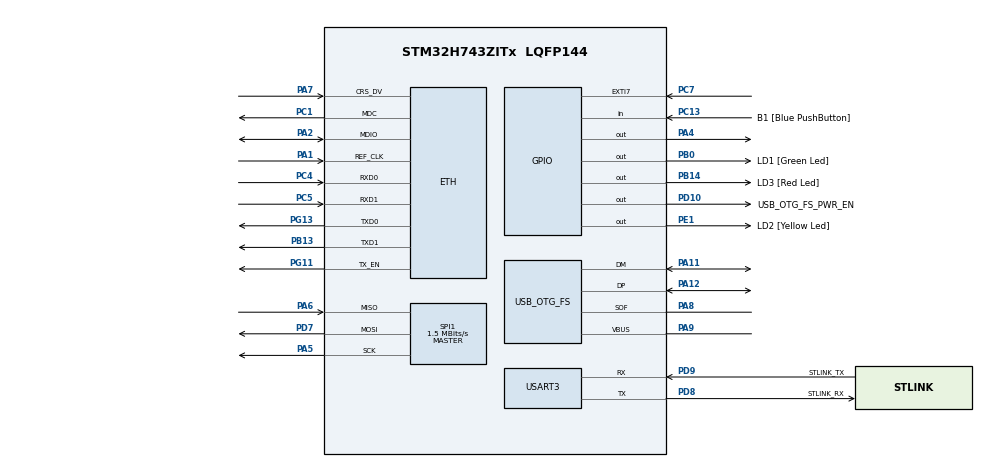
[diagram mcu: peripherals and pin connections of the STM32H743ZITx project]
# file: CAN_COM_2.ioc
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ETH.MediaInterface=HAL_ETH_RMII_MODE
Mcu.Family=STM32H7
Mcu.Name=STM32H743ZITx
Mcu.Package=LQFP144
NVIC.EXTI9_5_IRQn=true\:0\:0\:false\:false\:true\:true\:true\:true
NVIC.PriorityGroup=NVIC_PRIORITYGROUP_4
NVIC.RCC_IRQn=true\:0\:0\:false\:false\:true\:true\:false\:true
NVIC.TIM2_IRQn=true\:0\:0\:false\:false\:true\:true\:true\:true
NVIC.USART3_IRQn=true\:0\:0\:false\:false\:true\:true\:true\:true
PA1.Mode=RMII
PA1.Signal=ETH_REF_CLK
PA11.Mode=Device_Only
PA11.Signal=USB_OTG_FS_DM
PA12.Mode=Device_Only
PA12.Signal=USB_OTG_FS_DP
PA2.Mode=RMII
PA2.Signal=ETH_MDIO
PA4.Signal=GPIO_Output
PA5.Mode=Full_Duplex_Master
PA5.Signal=SPI1_SCK
PA6.Mode=Full_Duplex_Master
PA6.Signal=SPI1_MISO
PA7.Mode=RMII
PA7.Signal=ETH_CRS_DV
PA8.Mode=Activate_SOF_FS
PA8.Signal=USB_OTG_FS_SOF
PA9.Mode=Activate_VBUS
PA9.Signal=USB_OTG_FS_VBUS
PB0.GPIO_Label=LD1 [Green Led]
PB0.Signal=GPIO_Output
PB13.Mode=RMII
PB13.Signal=ETH_TXD1
PB14.GPIO_Label=LD3 [Red Led]
PB14.Signal=GPIO_Output
PC1.Mode=RMII
PC1.Signal=ETH_MDC
PC13.GPIO_Label=B1 [Blue PushButton]
PC13.Signal=GPIO_Input
PC14-OSC32_IN\ (OSC32_IN).Mode=LSE-External-Oscillator
PC14-OSC32_IN\ (OSC32_IN).Signal=RCC_OSC32_IN
PC15-OSC32_OUT\ (OSC32_OUT).Mode=LSE-External-Oscillator
PC15-OSC32_OUT\ (OSC32_OUT).Signal=RCC_OSC32_OUT
PC4.Mode=RMII
PC4.Signal=ETH_RXD0
PC5.Mode=RMII
PC5.Signal=ETH_RXD1
PC7.GPIO_ModeDefaultEXTI=GPIO_MODE_IT_FALLING
PC7.Signal=GPXTI7
PD10.GPIO_Label=USB_OTG_FS_PWR_EN
PD10.Signal=GPIO_Output
PD7.Mode=Full_Duplex_Master
PD7.Signal=SPI1_MOSI
PD8.GPIO_Label=STLINK_RX
PD8.Mode=Asynchronous
PD8.Signal=USART3_TX
PD9.GPIO_Label=STLINK_TX
PD9.Mode=Asynchronous
PD9.Signal=USART3_RX
PE1.GPIO_Label=LD2 [Yellow Led]
PE1.Signal=GPIO_Output
PG11.Mode=RMII
PG11.Signal=ETH_TX_EN
PG13.Mode=RMII
PG13.Signal=ETH_TXD0
PH0-OSC_IN\ (PH0).Mode=HSE-External-Clock-Source
PH0-OSC_IN\ (PH0).Signal=RCC_OSC_IN
PH1-OSC_OUT\ (PH1).Signal=RCC_OSC_OUT
ProjectManager.HeapSize=0x200
ProjectManager.StackSize=0x400
ProjectManager.TargetToolchain=STM32CubeIDE
RCC.ADCFreq_Value=16125000
RCC.APB1Freq_Value=64000000
RCC.APB2Freq_Value=64000000
RCC.APB3Freq_Value=64000000
RCC.APB4Freq_Value=64000000
RCC.CortexFreq_Value=64000000
RCC.DIVM1=1
RCC.DIVN1=24
RCC.DIVQ1=4
RCC.HCLKFreq_Value=64000000
RCC.HSE_VALUE=8000000
RCC.PLLFRACN=0
RCC.PWR_Regulator_Voltage_Scale=PWR_REGULATOR_VOLTAGE_SCALE2
RCC.SYSCLKFreq_VALUE=64000000
RCC.USBFreq_Value=48000000
SPI1.BaudRatePrescaler=SPI_BAUDRATEPRESCALER_32
SPI1.CalculateBaudRate=1.5 MBits/s
SPI1.DataSize=SPI_DATASIZE_8BIT
SPI1.Direction=SPI_DIRECTION_2LINES
SPI1.Mode=SPI_MODE_MASTER
SPI1.NSSPMode=SPI_NSS_PULSE_DISABLE
SPI1.VirtualType=VM_MASTER
TIM13.Prescaler=63
TIM2.AutoReloadPreload=TIM_AUTORELOAD_PRELOAD_ENABLE
TIM2.Period=1920
TIM2.Prescaler=1000
USART3.VirtualMode-Asynchronous=VM_ASYNC
USB_OTG_FS.VirtualMode=Device_Only
VP_TIM13_VS_ClockSourceINT.Mode=Enable_Timer
VP_TIM2_VS_ClockSourceINT.Mode=Internal
board=NUCLEO-H743ZI2

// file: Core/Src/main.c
/* USER CODE BEGIN Header */
/**
  ******************************************************************************
  * @file           : main.c
  * @brief          : Main program body
  ******************************************************************************
  * @attention
  *
  * Copyright (c) 2022 STMicroelectronics.
  * All rights reserved.
  *
  * This software is licensed under terms that can be found in the LICENSE file
  * in the root directory of this software component.
  * If no LICENSE file comes with this software, it is provided AS-IS.
  *
  ******************************************************************************
  */
/* USER CODE END Header */

#include "main.h"
#include "string.h"

/* USER CODE BEGIN Includes */

#include "CANSPI.h"
//#ifndef __HEADERS
#include "MCP2515.h"
//#endif
/* USER CODE END Includes */

#if defined ( __ICCARM__ ) /*!< IAR Compiler */
#pragma location=0x30000000
ETH_DMADescTypeDef  DMARxDscrTab[ETH_RX_DESC_CNT]; /* Ethernet Rx DMA Descriptors */
#pragma location=0x30000200
ETH_DMADescTypeDef  DMATxDscrTab[ETH_TX_DESC_CNT]; /* Ethernet Tx DMA Descriptors */
#pragma location=0x30000260
uint8_t Rx_Buff[ETH_RX_DESC_CNT][ETH_MAX_PACKET_SIZE]; /* Ethernet Receive Buffers */

#elif defined ( __CC_ARM )  /* MDK ARM Compiler */

__attribute__((at(0x30000000))) ETH_DMADescTypeDef  DMARxDscrTab[ETH_RX_DESC_CNT]; /* Ethernet Rx DMA Descriptors */
__attribute__((at(0x30000200))) ETH_DMADescTypeDef  DMATxDscrTab[ETH_TX_DESC_CNT]; /* Ethernet Tx DMA Descriptors */
__attribute__((at(0x30000260))) uint8_t Rx_Buff[ETH_RX_DESC_CNT][ETH_MAX_PACKET_SIZE]; /* Ethernet Receive Buffer */

#elif defined ( __GNUC__ ) /* GNU Compiler */
ETH_DMADescTypeDef DMARxDscrTab[ETH_RX_DESC_CNT] __attribute__((section(".RxDecripSection"))); /* Ethernet Rx DMA Descriptors */
ETH_DMADescTypeDef DMATxDscrTab[ETH_TX_DESC_CNT] __attribute__((section(".TxDecripSection")));   /* Ethernet Tx DMA Descriptors */
uint8_t Rx_Buff[ETH_RX_DESC_CNT][ETH_MAX_PACKET_SIZE] __attribute__((section(".RxArraySection"))); /* Ethernet Receive Buffers */
#endif

ETH_TxPacketConfig TxConfig;

ETH_HandleTypeDef heth;

SPI_HandleTypeDef hspi1;

TIM_HandleTypeDef htim2;
TIM_HandleTypeDef htim13;

UART_HandleTypeDef huart3;

PCD_HandleTypeDef hpcd_USB_OTG_FS;

void SystemClock_Config(void);
static void MX_GPIO_Init(void);
static void MX_ETH_Init(void);
static void MX_USART3_UART_Init(void);
static void MX_USB_OTG_FS_PCD_Init(void);
static void MX_SPI1_Init(void);
static void MX_TIM2_Init(void);
static void MX_TIM13_Init(void);

int main(void)
{

  /* MCU Configuration--------------------------------------------------------*/

  /* Reset of all peripherals, Initializes the Flash interface and the Systick. */
  HAL_Init();

  /* Configure the system clock */
  SystemClock_Config();

  /* Initialize all configured peripherals */
  MX_GPIO_Init();
  MX_ETH_Init();
  MX_USART3_UART_Init();
  MX_USB_OTG_FS_PCD_Init();
  MX_SPI1_Init();
  MX_TIM2_Init();
  MX_TIM13_Init();

  /* Infinite loop */
  while (1)
  {

  }
}

void SystemClock_Config(void)
{
  RCC_OscInitTypeDef RCC_OscInitStruct = {0};
  RCC_ClkInitTypeDef RCC_ClkInitStruct = {0};

  /** Supply configuration update enable
  */
  HAL_PWREx_ConfigSupply(PWR_LDO_SUPPLY);

  /** Configure the main internal regulator output voltage
  */
  __HAL_PWR_VOLTAGESCALING_CONFIG(PWR_REGULATOR_VOLTAGE_SCALE2);

  while(!__HAL_PWR_GET_FLAG(PWR_FLAG_VOSRDY)) {}

  /** Initializes the RCC Oscillators according to the specified parameters
  * in the RCC_OscInitTypeDef structure.
  */
  RCC_OscInitStruct.OscillatorType = RCC_OSCILLATORTYPE_HSI|RCC_OSCILLATORTYPE_HSE;
  RCC_OscInitStruct.HSEState = RCC_HSE_BYPASS;
  RCC_OscInitStruct.HSIState = RCC_HSI_DIV1;
  RCC_OscInitStruct.HSICalibrationValue = RCC_HSICALIBRATION_DEFAULT;
  RCC_OscInitStruct.PLL.PLLState = RCC_PLL_ON;
  RCC_OscInitStruct.PLL.PLLSource = RCC_PLLSOURCE_HSE;
  RCC_OscInitStruct.PLL.PLLM = 1;
  RCC_OscInitStruct.PLL.PLLN = 24;
  RCC_OscInitStruct.PLL.PLLP = 2;
  RCC_OscInitStruct.PLL.PLLQ = 4;
  RCC_OscInitStruct.PLL.PLLR = 2;
  RCC_OscInitStruct.PLL.PLLRGE = RCC_PLL1VCIRANGE_3;
  RCC_OscInitStruct.PLL.PLLVCOSEL = RCC_PLL1VCOWIDE;
  RCC_OscInitStruct.PLL.PLLFRACN = 0;
  if (HAL_RCC_OscConfig(&RCC_OscInitStruct) != HAL_OK)
  {
    Error_Handler();
  }

  /** Initializes the CPU, AHB and APB buses clocks
  */
  RCC_ClkInitStruct.ClockType = RCC_CLOCKTYPE_HCLK|RCC_CLOCKTYPE_SYSCLK
                              |RCC_CLOCKTYPE_PCLK1|RCC_CLOCKTYPE_PCLK2
                              |RCC_CLOCKTYPE_D3PCLK1|RCC_CLOCKTYPE_D1PCLK1;
  RCC_ClkInitStruct.SYSCLKSource = RCC_SYSCLKSOURCE_HSI;
  RCC_ClkInitStruct.SYSCLKDivider = RCC_SYSCLK_DIV1;
  RCC_ClkInitStruct.AHBCLKDivider = RCC_HCLK_DIV1;
  RCC_ClkInitStruct.APB3CLKDivider = RCC_APB3_DIV1;
  RCC_ClkInitStruct.APB1CLKDivider = RCC_APB1_DIV1;
  RCC_ClkInitStruct.APB2CLKDivider = RCC_APB2_DIV1;
  RCC_ClkInitStruct.APB4CLKDivider = RCC_APB4_DIV1;

  if (HAL_RCC_ClockConfig(&RCC_ClkInitStruct, FLASH_LATENCY_1) != HAL_OK)
  {
    Error_Handler();
  }
}

static void MX_ETH_Init(void)
{

   static uint8_t MACAddr[6];

  heth.Instance = ETH;
  MACAddr[0] = 0x00;
  MACAddr[1] = 0x80;
  MACAddr[2] = 0xE1;
  MACAddr[3] = 0x00;
  MACAddr[4] = 0x00;
  MACAddr[5] = 0x00;
  heth.Init.MACAddr = &MACAddr[0];
  heth.Init.MediaInterface = HAL_ETH_RMII_MODE;
  heth.Init.TxDesc = DMATxDscrTab;
  heth.Init.RxDesc = DMARxDscrTab;
  heth.Init.RxBuffLen = 1524;

  if (HAL_ETH_Init(&heth) != HAL_OK)
  {
    Error_Handler();
  }

  memset(&TxConfig, 0 , sizeof(ETH_TxPacketConfig));
  TxConfig.Attributes = ETH_TX_PACKETS_FEATURES_CSUM | ETH_TX_PACKETS_FEATURES_CRCPAD;
  TxConfig.ChecksumCtrl = ETH_CHECKSUM_IPHDR_PAYLOAD_INSERT_PHDR_CALC;
  TxConfig.CRCPadCtrl = ETH_CRC_PAD_INSERT;

}

static void MX_SPI1_Init(void)
{

  /* SPI1 parameter configuration*/
  hspi1.Instance = SPI1;
  hspi1.Init.Mode = SPI_MODE_MASTER;
  hspi1.Init.Direction = SPI_DIRECTION_2LINES;
  hspi1.Init.DataSize = SPI_DATASIZE_8BIT;
  hspi1.Init.CLKPolarity = SPI_POLARITY_LOW;
  hspi1.Init.CLKPhase = SPI_PHASE_1EDGE;
  hspi1.Init.NSS = SPI_NSS_SOFT;
  hspi1.Init.BaudRatePrescaler = SPI_BAUDRATEPRESCALER_32;
  hspi1.Init.FirstBit = SPI_FIRSTBIT_MSB;
  hspi1.Init.TIMode = SPI_TIMODE_DISABLE;
  hspi1.Init.CRCCalculation = SPI_CRCCALCULATION_DISABLE;
  hspi1.Init.CRCPolynomial = 0x0;
  hspi1.Init.NSSPMode = SPI_NSS_PULSE_DISABLE;
  hspi1.Init.NSSPolarity = SPI_NSS_POLARITY_LOW;
  hspi1.Init.FifoThreshold = SPI_FIFO_THRESHOLD_01DATA;
  hspi1.Init.TxCRCInitializationPattern = SPI_CRC_INITIALIZATION_ALL_ZERO_PATTERN;
  hspi1.Init.RxCRCInitializationPattern = SPI_CRC_INITIALIZATION_ALL_ZERO_PATTERN;
  hspi1.Init.MasterSSIdleness = SPI_MASTER_SS_IDLENESS_00CYCLE;
  hspi1.Init.MasterInterDataIdleness = SPI_MASTER_INTERDATA_IDLENESS_00CYCLE;
  hspi1.Init.MasterReceiverAutoSusp = SPI_MASTER_RX_AUTOSUSP_DISABLE;
  hspi1.Init.MasterKeepIOState = SPI_MASTER_KEEP_IO_STATE_DISABLE;
  hspi1.Init.IOSwap = SPI_IO_SWAP_DISABLE;
  if (HAL_SPI_Init(&hspi1) != HAL_OK)
  {
    Error_Handler();
  }

}

static void MX_TIM2_Init(void)
{

  TIM_ClockConfigTypeDef sClockSourceConfig = {0};
  TIM_MasterConfigTypeDef sMasterConfig = {0};

  htim2.Instance = TIM2;
  htim2.Init.Prescaler = 1000;
  htim2.Init.CounterMode = TIM_COUNTERMODE_UP;
  htim2.Init.Period = 1920;
  htim2.Init.ClockDivision = TIM_CLOCKDIVISION_DIV1;
  htim2.Init.AutoReloadPreload = TIM_AUTORELOAD_PRELOAD_ENABLE;
  if (HAL_TIM_Base_Init(&htim2) != HAL_OK)
  {
    Error_Handler();
  }
  sClockSourceConfig.ClockSource = TIM_CLOCKSOURCE_INTERNAL;
  if (HAL_TIM_ConfigClockSource(&htim2, &sClockSourceConfig) != HAL_OK)
  {
    Error_Handler();
  }
  sMasterConfig.MasterOutputTrigger = TIM_TRGO_RESET;
  sMasterConfig.MasterSlaveMode = TIM_MASTERSLAVEMODE_DISABLE;
  if (HAL_TIMEx_MasterConfigSynchronization(&htim2, &sMasterConfig) != HAL_OK)
  {
    Error_Handler();
  }

}

static void MX_TIM13_Init(void)
{

  htim13.Instance = TIM13;
  htim13.Init.Prescaler = 63;
  htim13.Init.CounterMode = TIM_COUNTERMODE_UP;
  htim13.Init.Period = 65535;
  htim13.Init.ClockDivision = TIM_CLOCKDIVISION_DIV1;
  htim13.Init.AutoReloadPreload = TIM_AUTORELOAD_PRELOAD_DISABLE;
  if (HAL_TIM_Base_Init(&htim13) != HAL_OK)
  {
    Error_Handler();
  }

}

static void MX_USART3_UART_Init(void)
{

  huart3.Instance = USART3;
  huart3.Init.BaudRate = 115200;
  huart3.Init.WordLength = UART_WORDLENGTH_8B;
  huart3.Init.StopBits = UART_STOPBITS_1;
  huart3.Init.Parity = UART_PARITY_NONE;
  huart3.Init.Mode = UART_MODE_TX_RX;
  huart3.Init.HwFlowCtl = UART_HWCONTROL_NONE;
  huart3.Init.OverSampling = UART_OVERSAMPLING_16;
  huart3.Init.OneBitSampling = UART_ONE_BIT_SAMPLE_DISABLE;
  huart3.Init.ClockPrescaler = UART_PRESCALER_DIV1;
  huart3.AdvancedInit.AdvFeatureInit = UART_ADVFEATURE_NO_INIT;
  if (HAL_UART_Init(&huart3) != HAL_OK)
  {
    Error_Handler();
  }
  if (HAL_UARTEx_SetTxFifoThreshold(&huart3, UART_TXFIFO_THRESHOLD_1_8) != HAL_OK)
  {
    Error_Handler();
  }
  if (HAL_UARTEx_SetRxFifoThreshold(&huart3, UART_RXFIFO_THRESHOLD_1_8) != HAL_OK)
  {
    Error_Handler();
  }
  if (HAL_UARTEx_DisableFifoMode(&huart3) != HAL_OK)
  {
    Error_Handler();
  }

}

static void MX_USB_OTG_FS_PCD_Init(void)
{

  hpcd_USB_OTG_FS.Instance = USB_OTG_FS;
  hpcd_USB_OTG_FS.Init.dev_endpoints = 9;
  hpcd_USB_OTG_FS.Init.speed = PCD_SPEED_FULL;
  hpcd_USB_OTG_FS.Init.dma_enable = DISABLE;
  hpcd_USB_OTG_FS.Init.phy_itface = PCD_PHY_EMBEDDED;
  hpcd_USB_OTG_FS.Init.Sof_enable = ENABLE;
  hpcd_USB_OTG_FS.Init.low_power_enable = DISABLE;
  hpcd_USB_OTG_FS.Init.lpm_enable = DISABLE;
  hpcd_USB_OTG_FS.Init.battery_charging_enable = ENABLE;
  hpcd_USB_OTG_FS.Init.vbus_sensing_enable = ENABLE;
  hpcd_USB_OTG_FS.Init.use_dedicated_ep1 = DISABLE;
  if (HAL_PCD_Init(&hpcd_USB_OTG_FS) != HAL_OK)
  {
    Error_Handler();
  }

}

static void MX_GPIO_Init(void)
{
  GPIO_InitTypeDef GPIO_InitStruct = {0};

  /* GPIO Ports Clock Enable */
  __HAL_RCC_GPIOC_CLK_ENABLE();
  __HAL_RCC_GPIOH_CLK_ENABLE();
  __HAL_RCC_GPIOA_CLK_ENABLE();
  __HAL_RCC_GPIOB_CLK_ENABLE();
  __HAL_RCC_GPIOD_CLK_ENABLE();
  __HAL_RCC_GPIOG_CLK_ENABLE();
  __HAL_RCC_GPIOE_CLK_ENABLE();

  /*Configure GPIO pin Output Level */
  HAL_GPIO_WritePin(GPIOA, GPIO_PIN_4, GPIO_PIN_RESET);

  /*Configure GPIO pin Output Level */
  HAL_GPIO_WritePin(GPIOB, LD1_Pin|LD3_Pin, GPIO_PIN_RESET);

  /*Configure GPIO pin Output Level */
  HAL_GPIO_WritePin(USB_OTG_FS_PWR_EN_GPIO_Port, USB_OTG_FS_PWR_EN_Pin, GPIO_PIN_RESET);

  /*Configure GPIO pin Output Level */
  HAL_GPIO_WritePin(LD2_GPIO_Port, LD2_Pin, GPIO_PIN_RESET);

  /*Configure GPIO pin : B1_Pin */
  GPIO_InitStruct.Pin = B1_Pin;
  GPIO_InitStruct.Mode = GPIO_MODE_INPUT;
  GPIO_InitStruct.Pull = GPIO_NOPULL;
  HAL_GPIO_Init(B1_GPIO_Port, &GPIO_InitStruct);

  /*Configure GPIO pin : PA4 */
  GPIO_InitStruct.Pin = GPIO_PIN_4;
  GPIO_InitStruct.Mode = GPIO_MODE_OUTPUT_PP;
  GPIO_InitStruct.Pull = GPIO_NOPULL;
  GPIO_InitStruct.Speed = GPIO_SPEED_FREQ_LOW;
  HAL_GPIO_Init(GPIOA, &GPIO_InitStruct);

  /*Configure GPIO pins : LD1_Pin LD3_Pin */
  GPIO_InitStruct.Pin = LD1_Pin|LD3_Pin;
  GPIO_InitStruct.Mode = GPIO_MODE_OUTPUT_PP;
  GPIO_InitStruct.Pull = GPIO_NOPULL;
  GPIO_InitStruct.Speed = GPIO_SPEED_FREQ_LOW;
  HAL_GPIO_Init(GPIOB, &GPIO_InitStruct);

  /*Configure GPIO pin : USB_OTG_FS_PWR_EN_Pin */
  GPIO_InitStruct.Pin = USB_OTG_FS_PWR_EN_Pin;
  GPIO_InitStruct.Mode = GPIO_MODE_OUTPUT_PP;
  GPIO_InitStruct.Pull = GPIO_NOPULL;
  GPIO_InitStruct.Speed = GPIO_SPEED_FREQ_LOW;
  HAL_GPIO_Init(USB_OTG_FS_PWR_EN_GPIO_Port, &GPIO_InitStruct);

  /*Configure GPIO pin : PC7 */
  GPIO_InitStruct.Pin = GPIO_PIN_7;
  GPIO_InitStruct.Mode = GPIO_MODE_IT_FALLING;
  GPIO_InitStruct.Pull = GPIO_NOPULL;
  HAL_GPIO_Init(GPIOC, &GPIO_InitStruct);

  /*Configure GPIO pin : LD2_Pin */
  GPIO_InitStruct.Pin = LD2_Pin;
  GPIO_InitStruct.Mode = GPIO_MODE_OUTPUT_PP;
  GPIO_InitStruct.Pull = GPIO_NOPULL;
  GPIO_InitStruct.Speed = GPIO_SPEED_FREQ_LOW;
  HAL_GPIO_Init(LD2_GPIO_Port, &GPIO_InitStruct);

  /* EXTI interrupt init*/
  HAL_NVIC_SetPriority(EXTI9_5_IRQn, 0, 0);
  HAL_NVIC_EnableIRQ(EXTI9_5_IRQn);

}

/* USER CODE BEGIN 4 */
void HAL_GPIO_EXTI_Callback(uint16_t GPIO_Pin)
{

}

void HAL_TIM_PeriodElapsedCallback(TIM_HandleTypeDef* htim)
{

}
/* USER CODE END 4 */

void Error_Handler(void)
{
  __disable_irq();
  while (1)
  {
  }
}
